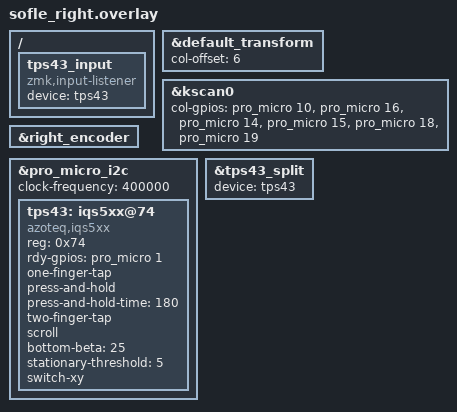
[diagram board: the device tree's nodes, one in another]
/*
 * Copyright (c) 2020 Ryan Cross
 *
 * SPDX-License-Identifier: MIT
 */

#include "sofle.dtsi"

&default_transform {
    col-offset = <6>;
};

&kscan0 {
    col-gpios
        = <&pro_micro 10 GPIO_ACTIVE_HIGH>
        , <&pro_micro 16 GPIO_ACTIVE_HIGH>
        , <&pro_micro 14 GPIO_ACTIVE_HIGH>
        , <&pro_micro 15 GPIO_ACTIVE_HIGH>
        , <&pro_micro 18 GPIO_ACTIVE_HIGH>
        , <&pro_micro 19 GPIO_ACTIVE_HIGH>
        ;
};

&right_encoder {
    status = "okay";
};

/ {
    tps43_input: tps43_input {
        compatible = "zmk,input-listener";
        device = <&tps43>;
    };
};

&pro_micro_i2c {
    status = "okay";
    clock-frequency = <400000>;
    tps43: iqs5xx@74 {
        status = "okay";
        compatible = "azoteq,iqs5xx";
        reg = <0x74>;

        rdy-gpios = <&pro_micro 1 GPIO_ACTIVE_HIGH>;

        /*
         * Potentially non-exhaustive list of configuration options.
         * See: dts/bindings/input/azoteq,iqs5xx-common.yaml for a full list.
         */
        one-finger-tap;
        press-and-hold;
        press-and-hold-time = <180>;
        two-finger-tap;

        scroll;

        bottom-beta = <25>;
        stationary-threshold = <5>;

        switch-xy;
    };
};

&tps43_split {
    device = <&tps43>;
};
